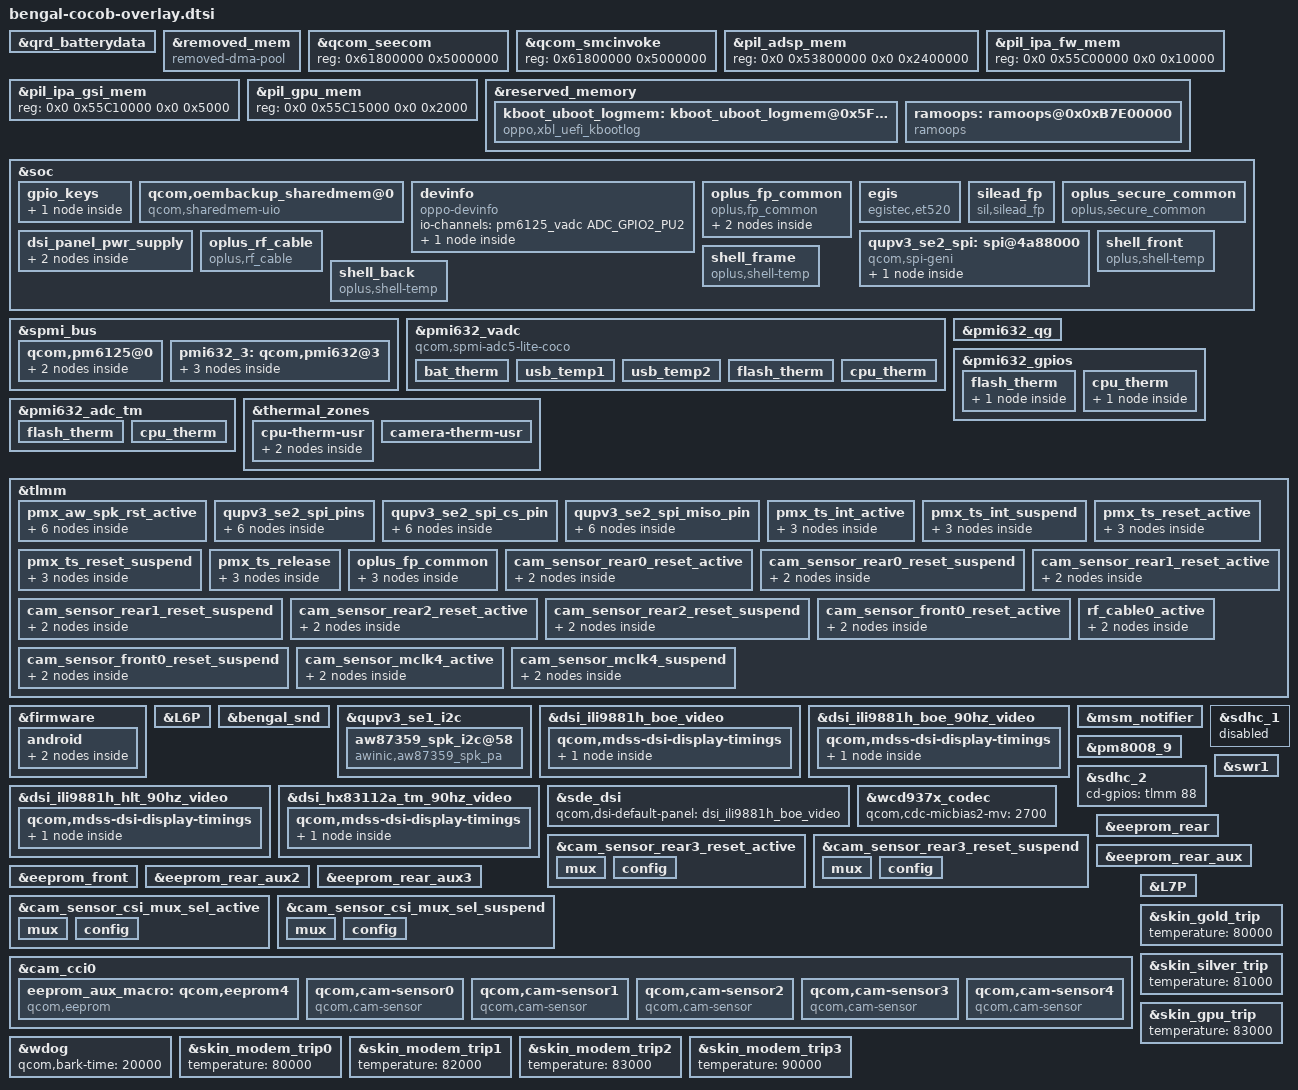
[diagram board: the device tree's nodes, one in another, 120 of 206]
/* *****************
the up part file change like:
delete note  and status = "disabled" to "ok"  add here also, other will meet can't boot issue or compile error issue
**************************/
#include "../../qcom/bengal-qrd.dtsi"
#include "dsi-panel-oplus20673-am643-samsung-fhd-video.dtsi"
#include "dsi-panel-oplus20673-s6e8fc1-samsung-fhd-video.dtsi"
//#ifdef OPLUS_BUG_STABILITY
#include "dsi-panel-ili9881h-boe-hd-vid.dtsi"
#include "dsi-panel-ili9881h-boe-hd-90hz-vid.dtsi"
#include "dsi-panel-ili9881h-hlt-hd-90hz-vid.dtsi"
#include "dsi-panel-hx83112a-tm-hd-90hz-vid.dtsi"
//#endif /* OPLUS_BUG_STABILITY */
#include "bengal-sia81xx.dtsi"

#include "nfc/coco-nfc-pn553.dtsi"

//bengal.dtsi

//#ifdef OPLUS_FEATURE_CHG_BASIC
&qrd_batterydata {
    /delete-node/ qcom,ATL466271_3300mAh;
    #include "oplus_battery_5000mah_1k_pmi632_Liwinon.dtsi"
    #include "oplus_battery_5000mah_15k_pmi632_Coslight.dtsi"
    #include "oplus_battery_5000mah_68k_pmi632_Atl.dtsi"
};
//#endif /* OPLUS_FEATURE_CHG_BASIC */
//#ifdef OPLUS_FEATURE_FINGERPRINT
&removed_mem {
	compatible = "removed-dma-pool";
	no-map;
	reg = <0x0 0x60000000 0x0 0x6800000>;
};
&qcom_seecom {
	/delete-property/ reg;
	reg = <0x61800000 0x5000000>;
};
&qcom_smcinvoke {
	/delete-property/ reg;
	reg = <0x61800000 0x5000000>;
};
//#endif /*OPLUS_FEATURE_FINGERPRINT*/

&pil_adsp_mem {
	/delete-property/ reg;
	reg = <0x0 0x53800000 0x0 0x2400000>;
};

&pil_ipa_fw_mem {
	/delete-property/ reg;
	reg = <0x0 0x55C00000 0x0 0x10000>;
};

&pil_ipa_gsi_mem {
	/delete-property/ reg;
	reg = <0x0 0x55C10000 0x0 0x5000>;
};

&pil_gpu_mem {
	/delete-property/ reg;
	reg = <0x0 0x55C15000 0x0 0x2000>;
};

// xbl_uefi_mem address get from boot_images Core.dsc.inc file: PcdEmbeddedFdBaseAddress + SERIAL_BUFFER_OFFSET,0x5FC00000+0x3F7000
// kernel boot log: 0x5FC00000~ 0x5FFF7000
&reserved_memory {

	kboot_uboot_logmem: kboot_uboot_logmem@0x5FC00000 {
		reg = <0x0 0x5FC00000 0x0 0x3FF000>;
		compatible = "oppo,xbl_uefi_kbootlog";
		xbluefi-offset = <0x3F7000>;
		no-map;
	};

	ramoops: ramoops@0x0xB7E00000 {
		compatible = "ramoops";
		reg = <0 0xB7E00000 0 0x00400000>;
		record-size =  <0x40000>; //256x1024
		console-size = <0x40000>;
		ftrace-size =  <0x40000>;
		pmsg-size=         <0x200000>;
		devinfo-size=  <0x01000>;
		ecc-size=          <0x0>;
	};
};
//bengal-qrd.dtsi
&soc {
	gpio_keys {
		vol_up {
			/delete-property/ label;
			label = "volume_down";
			/delete-property/ linux,code;
			linux,code = <KEY_VOLUMEDOWN>;
		};
	};
	//#ifdef VENDOR_EDIT
	//#ifdef FEATURE_OPPO_NV_BACKUP
	//add for creating a shared memory with uio for nv backup and restore
	qcom,oembackup_sharedmem@0 {
		compatible = "qcom,sharedmem-uio";
		reg = <0x0 0x00100000>;
		reg-names = "oembackup";
		qcom,client-id = <0x00000004>;
		qcom,guard-memory;
		qcom,vm-nav-path;
	};
	//#endif /* FEATURE_OPPO_NV_BACKUP */
	//#endif /* VENDOR_EDIT */

	devinfo {
		compatible = "oppo-devinfo";

		io-channels= <&pm6125_vadc ADC_GPIO2_PU2>;
		io-channel-names= "vph_pwr_voltage_sub";

		main-sub {
			compatible = "hw-match, main-sub";
			aboard-gpio0 = <&tlmm 68 0x1>;  //KB
			aboard-gpio1 = <&tlmm 101 0x1>; //MB
			//#ifndef VENDOR_EDIT
			//aboard-patterns = <0 0 0 0 0>;
			//#else
			aboard-patterns = <0 0 0 0 0 0>;
			//#endif

			/* main board */
			match-projects = <20671 20670 20672 20676 20679 0x2067C>;

		};
	};
	
	//#ifdef OPLUS_FEATURE_FINGERPRINT
	oplus_fp_common { //Slave driver and CS ID
        compatible = "oplus,fp_common"; //Manufacture, and Model
        oplus,fp_gpio_num = <1>;
        oplus,fp_gpio_0= <&tlmm 33 0x00>;//gpio33 ,1200 is gpio value
        pinctrl-names = "default";
        pinctrl-0 = <&gpio_id_default>;
	
        fp_egis {
		oplus,fp-id = <1>; /* fp id mapping table */
		vendor-chip = <18>; /* please refer to the struct fp_vendor_t in oppo_fp_commmon.h */
		eng-menu = "-1,-1"; /* represents SNR, inclination test item in engineer menu, and 0/1 means off/on */
		chip-name = "E_520";  /* /proc/fp_id, will be displayed in engineer menu  */
        };
		
        fp_silead {
            oplus,fp-id = <0>; /* fp id mapping table */
            vendor-chip = <21>; /* please refer to the struct fp_vendor_t in oppo_fp_commmon.h */
            eng-menu = "-1,-1"; /* represents SNR, inclination test item in engineer menu, and 0/1 means off/on */
            chip-name = "GSL_6150";  /* /proc/fp_id, will be displayed in engineer menu  */
        };
	};

	egis{
		status = "okay";
		compatible = "egistec,et520";
		interrupt-parent = <&tlmm>;
		interrupts = <34 0x00>;
		egistec,gpio_rst = <&tlmm 97 0x00>;
		egistec,gpio_irq = <&tlmm 34 0x00>;
	};
	
	silead_fp {
        compatible = "sil,silead_fp";
        qcom,qup-id = <5>;
        spi-max-frequency = <4800000>;
        reg = <0>;
        interrupt-parent = <&tlmm>;
        interrupts = <34 0x00>;
        rst-gpios = <&tlmm 97 0x00>;
        irq-gpios = <&tlmm 34 0x00>;
    };
	//#endif /*OPLUS_FEATURE_FINGERPRINT*/
    // #ifdef OPLUS_FEATURE_SECURITY_COMMON
    oplus_secure_common {
        compatible = "oplus,secure_common";
    };
    //#endif /* OPLUS_FEATURE_SECURITY_COMMON */

	//#ifdef OPLUS_BUG_STABILITY
	dsi_panel_pwr_supply {
		qcom,panel-supply-entry@1 {
			qcom,supply-min-voltage = <4600000>;
		};
		qcom,panel-supply-entry@2 {
			qcom,supply-min-voltage = <4600000>;
			qcom,supply-post-on-sleep = <2>;
		};
	};
	//#endif /* OPLUS_BUG_STABILITY */
        qupv3_se2_spi: spi@4a88000 {
                compatible = "qcom,spi-geni";
                #address-cells = <1>;
                #size-cells = <0>;
                reg = <0x4a88000 0x4000>;
                reg-names = "se_phys";
                clock-names = "se-clk", "m-ahb", "s-ahb";
                clocks = <&gcc GCC_QUPV3_WRAP0_S2_CLK>,
                        <&gcc GCC_QUPV3_WRAP_0_M_AHB_CLK>,
                        <&gcc GCC_QUPV3_WRAP_0_S_AHB_CLK>;
                pinctrl-names = "default", "sleep";
                pinctrl-0 = <&qupv3_se2_spi_active &qupv3_se2_spi_miso_active &qupv3_se2_spi_cs_active>;
                pinctrl-1 = <&qupv3_se2_spi_sleep &qupv3_se2_spi_miso_sleep &qupv3_se2_spi_cs_sleep>;

                interrupts = <GIC_SPI 329 IRQ_TYPE_LEVEL_HIGH>;
                spi-max-frequency = <50000000>;
                qcom,wrapper-core = <&qupv3_0>;
                dmas = <&gpi_dma0 0 2 1 64 0>,
                        <&gpi_dma0 1 2 1 64 0>;
                dma-names = "tx", "rx";
                status = "disabled";
        };
	//#ifdef VENDOR_EDIT
	oplus_rf_cable {
		compatible = "oplus,rf_cable";
		interrupt-parent = <&tlmm>;
		rf_cable_support_num = <1>;
		rf,cable0-gpio = <&tlmm 39 0>;
		rf,cable-support-timer = <0>;
		pinctrl-names = "rf_cable_active";
		pinctrl-0 = <&rf_cable0_active>;
	};
	//#endif /* VENDOR_EDIT */
	//#ifdef OPLUS_FEATURE_THERMAL_HORAE
	shell_front {
		compatible = "oplus,shell-temp";
	};

	shell_frame {
		compatible = "oplus,shell-temp";
	};

	shell_back {
		compatible = "oplus,shell-temp";
	};
	//#endif /* OPLUS_FEATURE_THERMAL_HORAE */
};
&spmi_bus {
	qcom,pm6125@0 {
		qcom,power-on@800 {
			qcom,pon_2 {
				qcom,pon-type = <1>;
				qcom,pull-up = <1>;
				linux,code = <KEY_VOLUMEUP>;
			};
		};
    };
        //#ifdef OPLUS_BUG_STABILITY
	pmi632_3: qcom,pmi632@3 {
		pmi632_lcdb: qpnp-lcdb@ec00 {
			qcom,pwrdn-delay-ms = <8>; //Possible values are 0, 1, 4, 8.
			lcdb_ldo_vreg: ldo {
				qcom,ldo-voltage-mv = <6000>;
			};
			lcdb_ncp_vreg: ncp {
				qcom,ldo-voltage-mv = <6000>;
			};
		};
	};
	//#endif /* OPLUS_BUG_STABILITY */
	//#ifdef OPLUS_FEATURE_CHG_BASIC

	//#endif /* OPLUS_FEATURE_CHG_BASIC */
};
//#ifdef OPLUS_FEATURE_CHG_BASIC
&pmi632_vadc{
			compatible = "qcom,spmi-adc5-lite-coco";
			bat_therm {
			    /delete-property/ reg;
			    reg = <ADC_BAT_THERM_PU1>;
		            qcom,lut-index = <2>;
			};
			usb_temp1 {
				reg = <ADC_GPIO1_PU2>;
				label = "usb_temp1";
				qcom,pre-scaling = <1 1>;
			};
			usb_temp2 {
				reg = <ADC_GPIO3_PU2>;
				label = "usb_temp2";
				qcom,pre-scaling = <1 1>;
			};
		};
&pmi632_qg{
		    /delete-property/ io-channels;
		    io-channels = <&pmi632_vadc ADC_BAT_THERM_PU1>,
		    		  <&pmi632_vadc ADC_PARALLEL_ISENSE>,
		                  <&pmi632_vadc ADC_BAT_ID_PU2>;
		    /delete-property/ io-channel-names;
	            io-channel-names = "batt-therm",
		                       "parallel_isense",
		                       "batt-id";
		    qcom,s3-entry-ibat-ua = <25000>;
		    qcom,s3-exit-ibat-ua = <38000>;
		    qcom,vbatt-cutoff-mv = <3390>;
		    qcom,fvss-enable;
                    qcom,project-index = <2>;// soda = 0; rum = 1; coco = 2
		    qcom,enable-qpnp-qg;	
		};
&pmi632_vadc {
    /delete-property/ pinctrl-0;
    pinctrl-0 = <&conn_therm_default &skin_therm_default &flash_therm_default &cpu_therm_default>;

	flash_therm {
		reg = <ADC_AMUX_THM1_PU2>;
		label = "flash_therm";
		qcom,ratiometric;
		qcom,hw-settle-time = <200>;
		qcom,pre-scaling = <1 1>;
	};

	cpu_therm {
		reg = <ADC_GPIO4_PU2>;
		label = "cpu_therm";
		qcom,ratiometric;
		qcom,hw-settle-time = <200>;
		qcom,pre-scaling = <1 1>;
	};	
};

&pmi632_gpios {
	flash_therm {
		flash_therm_default: flash_therm_default {
			pins = "gpio5";
			bias-high-impedance;
		};
	};

	cpu_therm {
		cpu_therm_default: cpu_therm_default {
			pins = "gpio6";
			bias-high-impedance;
		};
	};
};

&pmi632_adc_tm {
    /delete-property/ io-channels;
    io-channels = <&pmi632_vadc ADC_GPIO2_PU2>,
                  <&pmi632_vadc ADC_AMUX_THM1_PU2>,
		  <&pmi632_vadc ADC_GPIO4_PU2>;
		  
	flash_therm {
		reg = <ADC_AMUX_THM1_PU2>;
		qcom,ratiometric;
		qcom,hw-settle-time = <200>;
	};

	cpu_therm {
		reg = <ADC_GPIO4_PU2>;
		qcom,ratiometric;
		qcom,hw-settle-time = <200>;
	};
};

&thermal_zones {
    cpu-therm-usr {
	polling-delay-passive = <0>;
	polling-delay = <0>;
	thermal-governor = "user_space";
	thermal-sensors = <&pmi632_adc_tm ADC_GPIO4_PU2>;
	wake-capable-sensor;
	trips {
		active-config0 {
			temperature = <125000>;
			hysteresis = <1000>;
			type = "passive";
		};
	};
    };
    camera-therm-usr {
    /delete-property/ thermal-sensors;
    thermal-sensors = <&pmi632_adc_tm ADC_AMUX_THM1_PU2>;
    };
};
//#endif /* OPLUS_FEATURE_CHG_BASIC */
&tlmm {
	pmx_aw_spk_rst_active {
		aw_spk_reset_on: aw_spk_reset_on {
			mux {
				pins = "gpio111";
				function = "gpio";
			};

			config {
				pins = "gpio111";
				drive-strength = <8>;
				bias-pull-up;
			};
		};

		aw_spk_reset_off: aw_spk_reset_off {
			mux {
				pins = "gpio111";
				function = "gpio";
			};

			config {
				pins = "gpio111";
				drive-strength = <2>;
				bias-pull-down;
			};
		};
	};
	
	qupv3_se2_spi_pins: qupv3_se2_spi_pins {
		qupv3_se2_spi_active: qupv3_se2_spi_active {
			mux {
				pins = "gpio7", "gpio71";
				function = "qup2";
			};

			config {
				pins = "gpio7", "gpio71";
				drive-strength = <8>;
				output-low;
				bias-disable;
			};
		};

		qupv3_se2_spi_sleep: qupv3_se2_spi_sleep {
			mux {
				pins = "gpio7", "gpio71";
				function = "qup2";
			};

			configs {
				pins = "gpio7", "gpio71";
				drive-strength = <8>;
				output-low;
				bias-disable;
			};
		};
	};

	qupv3_se2_spi_cs_pin: qupv3_se2_spi_cs_pin {
		qupv3_se2_spi_cs_active: qupv3_se2_spi_cs_active {
			mux {
				pins = "gpio80";
				function = "qup2";
			};

			config {
				pins = "gpio80";
				drive-strength = <8>;
				output-high;
				bias-disable;
			};
		};

		qupv3_se2_spi_cs_sleep: qupv3_se2_spi_cs_sleep {
			mux {
				pins = "gpio80";
				function = "qup2";
			};

			configs {
				pins = "gpio80";
				drive-strength = <8>;
				output-high;
				bias-disable;
			};
		};
	};

	qupv3_se2_spi_miso_pin: qupv3_se2_spi_miso_pin {
		qupv3_se2_spi_miso_active: qupv3_se2_spi_miso_active {
			mux {
				pins = "gpio6";
				function = "qup2";
			};

			config {
				pins = "gpio6";
				drive-strength = <8>;
				bias-disable;
			};
		};

		qupv3_se2_spi_miso_sleep: qupv3_se2_spi_miso_sleep {
			mux {
				pins = "gpio6";
				function = "qup2";
			};

			configs {
				pins = "gpio6";
				drive-strength = <8>;
				bias-disable;
			};
		};
	};

	pmx_ts_int_active {
		ts_int_active: ts_int_active {
			mux {
				pins = "gpio104";
				function = "gpio";
			};

			config {
				pins = "gpio104";
				drive-strength = <8>;
				bias-pull-up;
			};
		};
	};

	pmx_ts_int_suspend {
		ts_int_suspend: ts_int_suspend {
			mux {
				pins = "gpio104";
				function = "gpio";
			};

			config {
				pins = "gpio104";
				drive-strength = <2>;
				bias-pull-up;
			};
		};
	};

	pmx_ts_reset_active {
		ts_reset_active: ts_reset_active {
			mux {
				pins = "gpio103";
				function = "gpio";
			};

			config {
				pins = "gpio103";
				drive-strength = <8>;
				bias-pull-up;
			};
		};
	};

	pmx_ts_reset_suspend {
		ts_reset_suspend: ts_reset_suspend {
			mux {
				pins = "gpio103";
				function = "gpio";
			};

			config {
				pins = "gpio103";
				drive-strength = <2>;
				bias-pull-down;
			};
		};
	};

	pmx_ts_release {
		ts_release: ts_release {
			mux {
				pins = "gpio103", "gpio104";
				function = "gpio";
			};

			config {
				pins = "gpio103", "gpio104";
				drive-strength = <2>;
				bias-pull-down;
			};
		};
	};
	
    //#ifdef OPLUS_FEATURE_FINGERPRINT
    oplus_fp_common{
		gpio_id_default: gpio_id_default {
			mux {
				pins = "gpio33";
				function = "gpio";
			};
			config {
				pins = "gpio33";
				drive-strength = <2>;
				bias-pull-up;
				input-enable;
			};
		};
	};
    //#endif
    
};

&firmware {
	android {
		fstab {
			vendor {
				/delete-property/ fsmgr_flags;
				fsmgr_flags = "wait,avb";
			};
		};
	};
};

&L6P {
	/delete-property/ regulator-min-microvolt;
	/delete-property/ regulator-max-microvolt;
	regulator-min-microvolt = <2800000>;
	regulator-max-microvolt = <3400000>;
};

&bengal_snd {
	/delete-property/ qcom,wsa-max-devs;
	/delete-property/ qcom,wsa-devs;
	qcom,wsa-max-devs = <0>;
	qcom,wsa-devs = <0>;
};

&qupv3_se1_i2c {
	/delete-node/ nq;

	aw87359_spk_i2c@58{
		compatible = "awinic,aw87359_spk_pa";
		reg = <0x58>;
		reset-gpio = <&tlmm 111 0x00>;
		pinctrl-names = "spk_reset_on", "spk_reset_off";
		pinctrl-0 = <&aw_spk_reset_on>;
		pinctrl-1 = <&aw_spk_reset_off>;
	};
};
&qupv3_se2_spi {
        /* Himax device tree node */
        status = "ok";
        ilitek_spi@0 {
                compatible = "tchip,ilitek";
                reg = <0>;
                chip-name = "NF_ILI9881H";
                status = "ok";

                spi-max-frequency = <12000000>;    //4800000,9600000,15000000,19200000
                reset-gpio = <&tlmm 103 0x00>;
                interrupt-parent = <&tlmm>;
                interrupts = <104 0x0>;
                irq-gpio = <&tlmm 104 0x2002>;

                touchpanel,max-num-support = <10>;
                touchpanel,tx-rx-num = <18 32>;
                touchpanel,panel-coords = <720 1600>;
                touchpanel,display-coords = <720 1600>;
                touchpanel,touchmajor-limit = <0 54>;

                platform_support_project = <20670 20671 20672 20676 20679 0x2067C>;
                platform_support_project_dir = <20671 20671 20671 20671 20671 20671>;
                platform_support_project_commandline = "ili9881h", "ili9881h", "ili9881h", "ili9881h", "ili9881h", "ili9881h";
                pinctrl-names = "default", "suspend";
                pinctrl-0 = <&ts_int_active &ts_reset_active>;
                pinctrl-1 = <&ts_int_suspend &ts_reset_suspend>;

                incell_screen;
                irq_need_dev_resume_ok;
                fw_edge_limit_support;
                black_gesture_support;
                charger_pump_support;
                headset_pump_support;
                esd_handle_support;
                //spurious_fingerprint_support;
                //lcd_trigger_fp_check;
                black_gesture_test_support;
                noflash_support;
                smart_gesture_support;
                pressure_report_support;
                fw_update_app_support;
                game_switch_support;
                drlimit_remove_support;
                lcd_trigger_load_tp_fw_support;
                suspend_gesture_cfg;
                fw_update_in_probe_with_headfile;

                touchpanel,button-type = <4>;
        };
};

//#ifdef OPLUS_BUG_STABILITY
&dsi_ili9881h_boe_video {
	qcom,panel-supply-entries = <&dsi_panel_pwr_supply>;
	qcom,mdss-dsi-bl-pmic-control-type = "bl_ctrl_dcs";
	pwms = <&pm6125_pwm 0 0>;
	qcom,bl-pmic-pwm-period-usecs = <100>;
	qcom,mdss-dsi-bl-min-level = <1>;
	qcom,mdss-dsi-bl-max-level = <4095>;
	qcom,mdss-brightness-max-level = <4095>;
	qcom,mdss-dsi-bl-normal-max-level = <2047>;
	qcom,mdss-brightness-normal-max-level = <2047>;
	qcom,mdss-brightness-default-level = <1024>;
	qcom,platform-reset-gpio = <&tlmm 85 0>;
	oplus,backlight-enable;
	//qcom,platform-bklight-en-gpio = <&pmi632_gpios 6 0>;
};
&dsi_ili9881h_boe_90hz_video {
	qcom,panel-supply-entries = <&dsi_panel_pwr_supply>;
	qcom,mdss-dsi-bl-pmic-control-type = "bl_ctrl_dcs";
	pwms = <&pm6125_pwm 0 0>;
	qcom,bl-pmic-pwm-period-usecs = <100>;
	qcom,mdss-dsi-bl-min-level = <1>;
	qcom,mdss-dsi-bl-max-level = <4095>;
	qcom,mdss-brightness-max-level = <4095>;
	qcom,mdss-dsi-bl-normal-max-level = <2047>;
	qcom,mdss-brightness-normal-max-level = <2047>;
	qcom,mdss-brightness-default-level = <1024>;
	qcom,platform-te-gpio = <&tlmm 81 0>;
	qcom,platform-reset-gpio = <&tlmm 85 0>;
	oplus,backlight-enable;
	//qcom,platform-bklight-en-gpio = <&pmi632_gpios 6 0>;
};

&dsi_ili9881h_hlt_90hz_video {
	qcom,panel-supply-entries = <&dsi_panel_pwr_supply>;
	qcom,mdss-dsi-bl-pmic-control-type = "bl_ctrl_dcs";
	pwms = <&pm6125_pwm 0 0>;
	qcom,bl-pmic-pwm-period-usecs = <100>;
	qcom,mdss-dsi-bl-min-level = <1>;
	qcom,mdss-dsi-bl-max-level = <4095>;
	qcom,mdss-brightness-max-level = <4095>;
	qcom,mdss-dsi-bl-normal-max-level = <2047>;
	qcom,mdss-brightness-normal-max-level = <2047>;
	qcom,mdss-brightness-default-level = <1024>;
	qcom,platform-reset-gpio = <&tlmm 85 0>;
	oplus,backlight-enable;
	//qcom,platform-bklight-en-gpio = <&pmi632_gpios 6 0>;
};

&dsi_hx83112a_tm_90hz_video {
	qcom,panel-supply-entries = <&dsi_panel_pwr_supply>;
	qcom,mdss-dsi-bl-pmic-control-type = "bl_ctrl_dcs";
	pwms = <&pm6125_pwm 0 0>;
	qcom,bl-pmic-pwm-period-usecs = <100>;
	qcom,mdss-dsi-bl-min-level = <1>;
	qcom,mdss-dsi-bl-max-level = <4095>;
	qcom,mdss-brightness-max-level = <4095>;
	qcom,mdss-dsi-bl-normal-max-level = <2047>;
	qcom,mdss-brightness-normal-max-level = <2047>;
	qcom,mdss-brightness-default-level = <1024>;
	qcom,platform-reset-gpio = <&tlmm 85 0>;
	oplus,backlight-enable;
	//qcom,platform-bklight-en-gpio = <&pmi632_gpios 6 0>;
};
//#endif /* OPLUS_BUG_STABILITY */

&sde_dsi {
	/delete-property/ qcom,dsi-default-panel;
	qcom,dsi-default-panel = <&dsi_ili9881h_boe_video>;
};
&msm_notifier {
	/delete-property/ panel;
	panel = <&dsi_s6e8fc1_samsung_video
		&dsi_s6e8fc1_samsung_video>;
};

&pm8008_9{
	status = "okay";
};

/* #ifdef OPLUS_FEATURE_EMMC_DRIVER */
&sdhc_1 {
       status = "disabled";
};

&sdhc_2 {
       cd-gpios = <&tlmm 88 GPIO_ACTIVE_HIGH>;
       status = "ok";
};
/* #endif */

//bengal-audio-overlay.dtsi
&swr1 {
	/delete-property/ qcom,disable-div2-clk-switch;
};
&wcd937x_codec {
	/delete-property/ qcom,cdc-micbias2-mv;
	qcom,cdc-micbias2-mv = <2700>;
};

&bengal_snd {
	/delete-property/ qcom,wsa-max-devs;
	/delete-property/ qcom,wsa-devs;
	qcom,wsa-max-devs = <0>;
	qcom,wsa-devs = <0>;
};

//bengal-camera-sensor-qrd.dtsi
&tlmm {
	cam_sensor_rear0_reset_active: cam_sensor_rear0_reset_active {
		mux {
			pins = "gpio18";
			function = "gpio";
		};
		config {
			pins = "gpio18";
			bias-disable; /* No PULL */
			drive-strength = <2>; /* 2 MA */
		};
	};
	cam_sensor_rear0_reset_suspend: cam_sensor_rear0_reset_suspend {
		mux {
			pins = "gpio18";
			function = "gpio";
		};
		config {
			pins = "gpio18";
			bias-pull-down; /* PULL DOWN */
			drive-strength = <2>; /* 2 MA */
			output-low;
		};
	};
	cam_sensor_rear1_reset_active: cam_sensor_rear1_reset_active {
		mux {
			pins = "gpio19";
			function = "gpio";
		};
		config {
			pins = "gpio19";
			bias-disable; /* No PULL */
			drive-strength = <2>; /* 2 MA */
		};
	};
	cam_sensor_rear1_reset_suspend: cam_sensor_rear1_reset_suspend {
		mux {
			pins = "gpio19";
			function = "gpio";
		};
		config {
			pins = "gpio19";
			bias-pull-down; /* PULL DOWN */
			drive-strength = <2>; /* 2 MA */
			output-low;
		};
	};
	cam_sensor_rear2_reset_active: cam_sensor_rear2_reset_active {
		mux {
			pins = "gpio65";
			function = "gpio";
		};
		config {
			pins = "gpio65";
			bias-disable; /* No PULL */
			drive-strength = <2>; /* 2 MA */
		};
	};
	cam_sensor_rear2_reset_suspend: cam_sensor_rear2_reset_suspend {
		mux {
			pins = "gpio65";
			function = "gpio";
		};
		config {
			pins = "gpio65";
			bias-pull-down; /* PULL DOWN */
			drive-strength = <2>; /* 2 MA */
			output-low;
		};
	};
	cam_sensor_front0_reset_active: cam_sensor_front0_reset_active {
		mux {
			pins = "gpio24";
			function = "gpio";
		};
		config {
			pins = "gpio24";
			bias-disable; /* No PULL */
			drive-strength = <2>; /* 2 MA */
		};
	};
	cam_sensor_front0_reset_suspend: cam_sensor_front0_reset_suspend {
		mux {
			pins = "gpio24";
			function = "gpio";
		};
		config {
			pins = "gpio24";
			bias-pull-down; /* PULL DOWN */
			drive-strength = <2>; /* 2 MA */
			output-low;
		};
	};

	cam_sensor_mclk4_active: cam_sensor_mclk4_active {
		/* MCLK 4*/
		mux {
			pins = "gpio28";
			function = "cam_mclk";
		};

		config {
			pins = "gpio28";
			bias-disable; /* No PULL */
			drive-strength = <2>; /* 2 MA */
		};
	};

	cam_sensor_mclk4_suspend: cam_sensor_mclk4_suspend {
		/* MCLK 4*/
		mux {
			pins = "gpio28";
			function = "cam_mclk";
		};

		config {
			pins = "gpio28";
			bias-pull-down; /* PULL DOWN */
			drive-strength = <2>; /* 2 MA */
		};
	};
	//#ifdef VENDOR_EDIT
	rf_cable0_active: rf_cable0_active {
		mux {
			pins = "gpio39";
			function = "gpio";
		};
		config {
			pins = "gpio39";
			drive-strength = <2>;
			input-enable;
			bias-pull-up;
		};
	};
	//#endif /* VENDOR_EDIT */	
	

};

&cam_sensor_rear3_reset_active {
	mux {
		pins = "gpio32";
		function = "gpio";
	};
	config {
		pins = "gpio32";
		bias-disable; /* No PULL */
		drive-strength = <2>; /* 2 MA */
	};
};
&cam_sensor_rear3_reset_suspend {
	mux {
		pins = "gpio32";
		function = "gpio";
	};
	config {
		pins = "gpio32";
		bias-disable; /* No PULL */
		drive-strength = <2>; /* 2 MA */
	};
};
&L6P {
	regulator-min-microvolt = <1800000>;
	regulator-max-microvolt = <1800000>;
};
&eeprom_rear {
	/delete-property/ cam_vio-supply;
	/delete-property/ gpios;
	cam_vio-supply = <&L6P>;
	pinctrl-0 = <&cam_sensor_mclk0_active
				&cam_sensor_rear0_reset_active>;
	pinctrl-1 = <&cam_sensor_mclk0_suspend
				&cam_sensor_rear0_reset_suspend>;
	gpios = <&tlmm 20 0>,
			<&tlmm 18 0>;
	gpio-reset = <1>;
	gpio-req-tbl-num = <0 1>;
	gpio-req-tbl-flags = <1 0>;
	gpio-req-tbl-label = "CAMIF_MCLK0",
						"CAM_RESET0";
	sensor-mode = <0>;
	cci-master = <0>;
	status = "ok";
	clocks = <&gcc GCC_CAMSS_MCLK0_CLK>;
	clock-names = "cam_clk";
	clock-cntl-level = "turbo";
	clock-rates = <24000000>;
};

&eeprom_rear_aux {
	/delete-property/ cam_vio-supply;
	/delete-property/ pinctrl-0;
	/delete-property/ pinctrl-1;
	/delete-property/ gpios;
	/delete-property/ gpio-req-tbl-label;
	/delete-property/ clocks;
	cam_vio-supply = <&L6P>;
	pinctrl-0 = <&cam_sensor_mclk1_active
				&cam_sensor_rear1_reset_active>;
	pinctrl-1 = <&cam_sensor_mclk1_suspend
				&cam_sensor_rear1_reset_suspend>;
	gpios = <&tlmm 21 0>,
			<&tlmm 19 0>;
	gpio-reset = <1>;
	gpio-req-tbl-num = <0 1>;
	gpio-req-tbl-flags = <1 0>;
	gpio-req-tbl-label = "CAMIF_MCLK1",
						"CAM_RESET1";
	sensor-mode = <0>;
	cci-master = <1>;
	status = "ok";
	clocks = <&gcc GCC_CAMSS_MCLK1_CLK>;
	clock-names = "cam_clk";
	clock-cntl-level = "turbo";
	clock-rates = <19200000>;
};

&eeprom_front {
	/delete-property/ cam_vio-supply;
	/delete-property/ pinctrl-0;
	/delete-property/ pinctrl-1;
	/delete-property/ gpios;
	/delete-property/ gpio-req-tbl-label;
	/delete-property/ clocks;
	cam_vio-supply = <&L6P>;
	pinctrl-0 = <&cam_sensor_mclk2_active
				&cam_sensor_front0_reset_active>;
	pinctrl-1 = <&cam_sensor_mclk2_suspend
				&cam_sensor_front0_reset_suspend>;
	gpios = <&tlmm 27 0>,
			<&tlmm 24 0>;
	gpio-reset = <1>;
	gpio-req-tbl-num = <0 1>;
	gpio-req-tbl-flags = <1 0>;
	gpio-req-tbl-label = "CAMIF_MCLK2",
						"CAM_RESET2";
	sensor-mode = <0>;
	cci-master = <1>;
	status = "ok";
	clocks = <&gcc GCC_CAMSS_MCLK2_CLK>;
	clock-names = "cam_clk";
	clock-cntl-level = "turbo";
	clock-rates = <24000000>;
};

&eeprom_rear_aux2 {
	/delete-property/ cam_vio-supply;
	/delete-property/ pinctrl-0;
	/delete-property/ pinctrl-1;
	/delete-property/ gpios;
	/delete-property/ gpio-req-tbl-label;
	/delete-property/ clocks;
	/delete-property/ cci-master;
	cam_vio-supply = <&L6P>;
	pinctrl-0 = <&cam_sensor_mclk4_active
				&cam_sensor_rear3_reset_active
				&cam_sensor_csi_mux_sel_active>;
	pinctrl-1 = <&cam_sensor_mclk4_suspend
				&cam_sensor_rear3_reset_suspend
				&cam_sensor_csi_mux_sel_suspend>;
	gpios = <&tlmm 28 0>,
			<&tlmm 32 0>,
			<&tlmm 59 0>;
	gpio-reset = <1>;
	gpio-custom1 = <2>;
	gpio-req-tbl-num = <0 1 2>;
	gpio-req-tbl-flags = <1 0 0>;
	gpio-req-tbl-label = "CAMIF_MCLK4",
						"CAM_RESET4",
						"CAM_CSIMUX_SEL1";
	sensor-mode = <0>;
	cci-master = <0>;
	status = "ok";
	clocks = <&gcc GCC_CAMSS_MCLK3_CLK>;
	clock-names = "cam_clk";
	clock-cntl-level = "turbo";
	clock-rates = <24000000>;
};

&eeprom_rear_aux3 {
	/delete-property/ cam_vio-supply;
	/delete-property/ pinctrl-0;
	/delete-property/ pinctrl-1;
	/delete-property/ gpios;
	/delete-property/ gpio-req-tbl-label;
	/delete-property/ clocks;
	/delete-property/ cci-master;
	cam_vio-supply = <&L6P>;
	pinctrl-0 = <&cam_sensor_mclk2_active
				&cam_sensor_rear3_reset_active>;
	pinctrl-1 = <&cam_sensor_mclk2_suspend
				&cam_sensor_rear3_reset_suspend>;
	gpios = <&tlmm 27 0>,
			<&tlmm 18 0>;
	gpio-req-tbl-label = "CAMIF_MCLK2",
						"CAM_RESET4";
	cci-master = <1>;
	clocks = <&gcc GCC_CAMSS_MCLK2_CLK>;
};

&cam_sensor_csi_mux_sel_active {
	/*CSIMUX_SEL*/
	mux {
		pins = "gpio59";
		function = "gpio";
	};

	config {
		pins = "gpio59";
		bias-disable; /* No PULL */
		drive-strength = <2>; /* 2 MA */
	};
};
&cam_sensor_csi_mux_sel_suspend {
	/* CSIMUX_SEL */
	mux {
		pins = "gpio59";
		function = "gpio";
	};

	config {
		pins = "gpio59";
		bias-pull-down; /* PULL DOWN */
		drive-strength = <2>; /* 2 MA */
		output-low;
	};
};

&cam_cci0 {
	eeprom_aux_macro: qcom,eeprom4 {
		cell-index = <4>;
		compatible = "qcom,eeprom";
		cam_vio-supply = <&L6P>;
		cam_vana-supply = <&L4P>;
		cam_clk-supply = <&gcc_camss_top_gdsc>;
		regulator-names = "cam_vio", "cam_vana","cam_clk";
		rgltr-cntrl-support;
		pwm-switch;
		rgltr-min-voltage = <1800000 2800000 0>;
		rgltr-max-voltage = <1800000 2800000 0>;
		rgltr-load-current = <120000 80000 0>;
		gpio-no-mux = <0>;
		pinctrl-names = "cam_default", "cam_suspend";
		pinctrl-0 = <&cam_sensor_mclk4_active
				&cam_sensor_rear3_reset_active>;
		pinctrl-1 = <&cam_sensor_mclk4_suspend
				&cam_sensor_rear3_reset_suspend>;
		gpios = <&tlmm 28 0>,
			<&tlmm 32 0>;
		gpio-reset = <1>;
		gpio-req-tbl-num = <0 1>;
		gpio-req-tbl-flags = <1 0>;
		gpio-req-tbl-label = "CAMIF_MCLK4",
					"CAM_RESET4";
		sensor-mode = <0>;
		cci-master = <0>;
		status = "ok";
		clocks = <&gcc GCC_CAMSS_MCLK3_CLK>;
		clock-names = "cam_clk";
		clock-cntl-level = "turbo";
		clock-rates = <24000000>;
	};

	/* Rear*/
	qcom,cam-sensor0 {
		cell-index = <0>;
		compatible = "qcom,cam-sensor";
		csiphy-sd-index = <0>;
		sensor-position-roll = <90>;
		sensor-position-pitch = <0>;
		sensor-position-yaw = <180>;
		actuator-src = <&actuator_rear>;
		led-flash-src = <&led_flash_rear>;
		eeprom-src = <&eeprom_rear>;
		cam_vio-supply = <&L6P>;
		cam_vana-supply = <&L3P>;
		cam_vdig-supply = <&L1P>;
		cam_clk-supply = <&gcc_camss_top_gdsc>;
		cam_vaf-supply = <&L5P>;
		regulator-names = "cam_vio", "cam_vana", "cam_vdig",
			"cam_clk", "cam_vaf";
		rgltr-cntrl-support;
		pwm-switch;
		rgltr-min-voltage = <1800000 2800000 1200000 0 2800000>;
		rgltr-max-voltage = <1800000 2800000 1200000 0 2800000>;
		rgltr-load-current = <120000 80000 1200000 0 100000>;
		gpio-no-mux = <0>;
		pinctrl-names = "cam_default", "cam_suspend";
		pinctrl-0 = <&cam_sensor_mclk0_active
				&cam_sensor_rear0_reset_active>;
		pinctrl-1 = <&cam_sensor_mclk0_suspend
				&cam_sensor_rear0_reset_suspend>;
		gpios = <&tlmm 20 0>,
			<&tlmm 18 0>;
		gpio-reset = <1>;
		gpio-req-tbl-num = <0 1>;
		gpio-req-tbl-flags = <1 0>;
		gpio-req-tbl-label = "CAMIF_MCLK0",
					"CAM_RESET0";
		sensor-mode = <0>;
		cci-master = <0>;
		status = "ok";
		clocks = <&gcc GCC_CAMSS_MCLK0_CLK>;
		clock-names = "cam_clk";
		clock-cntl-level = "turbo";
		clock-rates = <24000000>;
	};

	/* Rear wide*/
	qcom,cam-sensor1 {
		cell-index = <1>;
		compatible = "qcom,cam-sensor";
		csiphy-sd-index = <1>;
		sensor-position-roll = <90>;
		sensor-position-pitch = <0>;
		sensor-position-yaw = <180>;
		//actuator-src = <&actuator_rear>;
		led-flash-src = <&led_flash_rear_aux>;
		eeprom-src = <&eeprom_rear_aux>;
		cam_vio-supply = <&L6P>;
		cam_vana-supply = <&L4P>;
		cam_vdig-supply = <&L2P>;
		cam_clk-supply = <&gcc_camss_top_gdsc>;
		regulator-names = "cam_vio", "cam_vana", "cam_vdig",
			"cam_clk";
		rgltr-cntrl-support;
		pwm-switch;
		rgltr-min-voltage = <1800000 2800000 1200000 0>;
		rgltr-max-voltage = <1800000 2800000 1200000 0>;
		rgltr-load-current = <120000 80000 1200000 0>;
		gpio-no-mux = <0>;
		pinctrl-names = "cam_default", "cam_suspend";
		pinctrl-0 = <&cam_sensor_mclk1_active
				&cam_sensor_rear1_reset_active>;
		pinctrl-1 = <&cam_sensor_mclk1_suspend
				&cam_sensor_rear1_reset_suspend>;
		gpios = <&tlmm 21 0>,
			<&tlmm 19 0>;
		gpio-reset = <1>;
		gpio-req-tbl-num = <0 1>;
		gpio-req-tbl-flags = <1 0>;
		gpio-req-tbl-label = "CAMIF_MCLK1",
					"CAM_RESET1";
		sensor-mode = <0>;
		cci-master = <1>;
		status = "ok";
		clocks = <&gcc GCC_CAMSS_MCLK1_CLK>;
		clock-names = "cam_clk";
		clock-cntl-level = "turbo";
		clock-rates = <19200000>;
	};

    /* Front*/
	qcom,cam-sensor2 {
		cell-index = <2>;
		compatible = "qcom,cam-sensor";
		csiphy-sd-index = <2>;
		sensor-position-roll = <270>;
		sensor-position-pitch = <0>;
		sensor-position-yaw = <0>;
		//actuator-src = <&actuator_rear>;
		//led-flash-src = <&led_flash_rear>;
		eeprom-src = <&eeprom_front>;
		cam_vio-supply = <&L6P>;
		cam_vana-supply = <&L4P>;
		cam_vdig-supply = <&L2P>;
		cam_clk-supply = <&gcc_camss_top_gdsc>;
		regulator-names = "cam_vio", "cam_vana", "cam_vdig",
			"cam_clk";
		rgltr-cntrl-support;
		pwm-switch;
		rgltr-min-voltage = <1800000 2800000 1200000 0>;
		rgltr-max-voltage = <1800000 2800000 1200000 0>;
		rgltr-load-current = <120000 80000 1200000 0>;
		gpio-no-mux = <0>;
		pinctrl-names = "cam_default", "cam_suspend";
		pinctrl-0 = <&cam_sensor_mclk2_active
				&cam_sensor_front0_reset_active>;
		pinctrl-1 = <&cam_sensor_mclk2_suspend
				&cam_sensor_front0_reset_suspend>;
		gpios = <&tlmm 27 0>,
			<&tlmm 24 0>;
		gpio-reset = <1>;
		gpio-req-tbl-num = <0 1>;
		gpio-req-tbl-flags = <1 0>;
		gpio-req-tbl-label = "CAMIF_MCLK2",
					"CAM_RESET2";
		sensor-mode = <0>;
		cci-master = <1>;
		status = "ok";
		clocks = <&gcc GCC_CAMSS_MCLK2_CLK>;
		clock-names = "cam_clk";
		clock-cntl-level = "turbo";
		clock-rates = <24000000>;
	};

	/*Aux Mono*/
	qcom,cam-sensor3 {
		cell-index = <3>;
		compatible = "qcom,cam-sensor";
		csiphy-sd-index = <1>;
		sensor-position-roll = <90>;
		sensor-position-pitch = <0>;
		sensor-position-yaw = <180>;
		//actuator-src = <&actuator_rear>;
		//led-flash-src = <&led_flash_rear>;
		//eeprom-src = <&eeprom_rear>;
		cam_vio-supply = <&L6P>;
		cam_vana-supply = <&L4P>;
		//cam_vdig-supply = <&L2P>;
		cam_clk-supply = <&gcc_camss_top_gdsc>;
		regulator-names = "cam_vio", "cam_vana", "cam_clk";
		rgltr-cntrl-support;
		pwm-switch;
		rgltr-min-voltage = <1800000 2800000 0>;
		rgltr-max-voltage = <1800000 2800000 0>;
		rgltr-load-current = <120000 80000 0>;
		gpio-no-mux = <0>;
		pinctrl-names = "cam_default", "cam_suspend";
		pinctrl-0 = <&cam_sensor_mclk3_active
				&cam_sensor_rear2_reset_active
				&cam_sensor_csi_mux_sel_active>;
		pinctrl-1 = <&cam_sensor_mclk3_suspend
				&cam_sensor_rear2_reset_suspend
				&cam_sensor_csi_mux_sel_suspend>;
		gpios = <&tlmm 28 0>,
			<&tlmm 65 0>,
			<&tlmm 59 0>;
		gpio-reset = <1>;
		gpio-custom1 = <2>;
		gpio-req-tbl-num = <0 1 2>;
		gpio-req-tbl-flags = <1 0 0>;
		gpio-req-tbl-label = "CAMIF_MCLK3",
					"CAM_RESET3",
					"CAM_CSIMUX_SEL1";
		sensor-mode = <0>;
		cci-master = <1>;
		status = "ok";
		clocks = <&gcc GCC_CAMSS_MCLK3_CLK>;
		clock-names = "cam_clk";
		clock-cntl-level = "turbo";
		clock-rates = <24000000>;
	};

    /*Aux Macro*/
	qcom,cam-sensor4 {
		cell-index = <4>;
		compatible = "qcom,cam-sensor";
		csiphy-sd-index = <1>;
		sensor-position-roll = <270>;
		sensor-position-pitch = <0>;
		sensor-position-yaw = <180>;
		//actuator-src = <&actuator_rear>;
		led-flash-src = <&led_flash_rear>;
		eeprom-src = <&eeprom_aux_macro>;
		cam_vio-supply = <&L6P>;
		cam_vana-supply = <&L4P>;
		//cam_vdig-supply = <&L2P>;
		cam_clk-supply = <&gcc_camss_top_gdsc>;
		regulator-names = "cam_vio", "cam_vana", "cam_clk";
		rgltr-cntrl-support;
		pwm-switch;
		rgltr-min-voltage = <1800000 2800000 0>;
		rgltr-max-voltage = <1800000 2800000 0>;
		rgltr-load-current = <120000 80000 0>;
		gpio-no-mux = <0>;
		pinctrl-names = "cam_default", "cam_suspend";
		pinctrl-0 = <&cam_sensor_mclk4_active
				&cam_sensor_rear3_reset_active
				&cam_sensor_csi_mux_sel_active>;
		pinctrl-1 = <&cam_sensor_mclk4_suspend
				&cam_sensor_rear3_reset_suspend
				&cam_sensor_csi_mux_sel_suspend>;
		gpios = <&tlmm 28 0>,
			<&tlmm 32 0>,
			<&tlmm 59 0>;
		gpio-reset = <1>;
		gpio-custom1 = <2>;
		gpio-req-tbl-num = <0 1 2>;
		gpio-req-tbl-flags = <1 0 0>;
		gpio-req-tbl-label = "CAMIF_MCLK4",
					"CAM_RESET4",
					"CAM_CSIMUX_SEL1";
		sensor-mode = <0>;
		cci-master = <0>;
		status = "ok";
		clocks = <&gcc GCC_CAMSS_MCLK3_CLK>;
		clock-names = "cam_clk";
		clock-cntl-level = "turbo";
		clock-rates = <24000000>;
	};
};

//#ifdef OPLUS_BUG_STABILITY
&dsi_ili9881h_boe_video {
	qcom,mdss-dsi-t-clk-post = <0x0C>;
	qcom,mdss-dsi-t-clk-pre = <0x28>;
	qcom,esd-check-enabled;
	qcom,mdss-dsi-panel-status-check-mode = "reg_read";
	qcom,mdss-dsi-panel-status-command = [06 01 00 01 00 00 01 0a];
	qcom,mdss-dsi-panel-status-command-state = "dsi_lp_mode";
	qcom,mdss-dsi-panel-status-value = <0x9c>;
	qcom,mdss-dsi-panel-on-check-value = <0x9c>;
	qcom,mdss-dsi-panel-status-read-length = <1>;
//	qcom,dsi-supported-dfps-list = <60 55 48>;
//	qcom,mdss-dsi-pan-enable-dynamic-fps;
//	qcom,mdss-dsi-pan-fps-update =
//		"dfps_immediate_porch_mode_vfp";
	qcom,dsi-select-clocks = "mux_byte_clk0", "mux_pixel_clk0",
				"src_byte_clk0", "src_pixel_clk0",
				"shadow_byte_clk0", "shadow_pixel_clk0";
//	qcom,dsi-dyn-clk-enable;
//	qcom,dsi-dyn-clk-list =
//		<976190400 988392784 984325320 980257864>;
//	qcom,dsi-dyn-clk-type = "constant-fps-adjust-vfp";
	qcom,mdss-dsi-display-timings {
		timing@0{
			qcom,mdss-dsi-panel-phy-timings =
				[21 1E 06 08 04 02 04 a0
				21 1E 06 08 04 02 04 a0
				21 1E 06 08 04 02 04 a0
				21 1E 06 08 04 02 04 a0
				21 15 06 07 04 02 04 a0];
			qcom,display-topology = <1 0 1>;
			qcom,default-topology-index = <0>;
		};
	};
};

&dsi_ili9881h_boe_90hz_video {
	qcom,mdss-dsi-t-clk-post = <0x0D>;
	qcom,mdss-dsi-t-clk-pre = <0x2E>;
	qcom,esd-check-enabled;
	qcom,mdss-dsi-panel-status-check-mode = "reg_read";
	qcom,mdss-dsi-panel-status-command = [06 01 00 01 00 00 01 0a];
	qcom,mdss-dsi-panel-status-command-state = "dsi_lp_mode";
	qcom,mdss-dsi-panel-status-value = <0x9c>;
	qcom,mdss-dsi-panel-on-check-value = <0x9c>;
	qcom,mdss-dsi-panel-status-read-length = <1>;
	qcom,dsi-supported-dfps-list = <60 90>;
	qcom,mdss-dsi-pan-enable-dynamic-fps;
	qcom,mdss-dsi-pan-fps-update =
		"dfps_immediate_porch_mode_vfp";
	qcom,mdss-dsi-min-refresh-rate = <60>;
	qcom,mdss-dsi-max-refresh-rate = <90>;
	qcom,dsi-select-clocks = "mux_byte_clk0", "mux_pixel_clk0",
				"src_byte_clk0", "src_pixel_clk0",
				"shadow_byte_clk0", "shadow_pixel_clk0";
	qcom,dsi-dyn-clk-enable;
	qcom,dsi-dyn-clk-list =
		<837423360 828118656>;
	qcom,dsi-dyn-clk-type = "constant-fps-adjust-hfp";
	qcom,mdss-dsi-display-timings {
		timing@0{
			qcom,mdss-dsi-panel-phy-timings =
				[23 1F 07 09 05 02 04 a0
				23 1F 07 09 05 02 04 a0
				23 1F 07 09 05 02 04 a0
				23 1F 07 09 05 02 04 a0
				23 1A 07 08 05 02 04 a0];
			qcom,display-topology = <1 0 1>;
			qcom,default-topology-index = <0>;
		};
	};
};

&dsi_ili9881h_hlt_90hz_video {
	qcom,mdss-dsi-t-clk-post = <0x0D>;
	qcom,mdss-dsi-t-clk-pre = <0x2E>;
	qcom,esd-check-enabled;
	qcom,mdss-dsi-panel-status-check-mode = "reg_read";
	qcom,mdss-dsi-panel-status-command = [06 01 00 01 00 00 01 0a];
	qcom,mdss-dsi-panel-status-command-state = "dsi_lp_mode";
	qcom,mdss-dsi-panel-status-value = <0x9c>;
	qcom,mdss-dsi-panel-on-check-value = <0x9c>;
	qcom,mdss-dsi-panel-status-read-length = <1>;
	qcom,dsi-supported-dfps-list = <60 90>;
	qcom,mdss-dsi-pan-enable-dynamic-fps;
	qcom,mdss-dsi-pan-fps-update =
		"dfps_immediate_porch_mode_vfp";
	qcom,mdss-dsi-min-refresh-rate = <60>;
	qcom,mdss-dsi-max-refresh-rate = <90>;
	qcom,dsi-select-clocks = "mux_byte_clk0", "mux_pixel_clk0",
				"src_byte_clk0", "src_pixel_clk0",
				"shadow_byte_clk0", "shadow_pixel_clk0";
	qcom,dsi-dyn-clk-enable;
	qcom,dsi-dyn-clk-list =
		<837423360 828118656>;
	qcom,dsi-dyn-clk-type = "constant-fps-adjust-hfp";
	qcom,mdss-dsi-display-timings {
		timing@0{
			qcom,mdss-dsi-panel-phy-timings =
				[23 1F 07 09 05 02 04 a0
				23 1F 07 09 05 02 04 a0
				23 1F 07 09 05 02 04 a0
				23 1F 07 09 05 02 04 a0
				23 1A 07 08 05 02 04 a0];
			qcom,display-topology = <1 0 1>;
			qcom,default-topology-index = <0>;
		};
	};
};

&dsi_hx83112a_tm_90hz_video {
	qcom,mdss-dsi-t-clk-post = <0x0D>;
	qcom,mdss-dsi-t-clk-pre = <0x2E>;
	qcom,esd-check-enabled;
	qcom,mdss-dsi-panel-status-check-mode = "reg_read";
	qcom,mdss-dsi-panel-status-command = [06 01 00 01 00 00 01 09];
	qcom,mdss-dsi-panel-status-command-state = "dsi_lp_mode";
	qcom,mdss-dsi-panel-status-value = <0x80 0x73 0x06>;
	qcom,mdss-dsi-panel-on-check-value = <0x80 0x73 0x06>;
	qcom,mdss-dsi-panel-status-read-length = <3>;
	qcom,dsi-supported-dfps-list = <60 90 45>;
	qcom,mdss-dsi-pan-enable-dynamic-fps;
	qcom,mdss-dsi-pan-fps-update =
		"dfps_immediate_porch_mode_vfp";
	qcom,mdss-dsi-min-refresh-rate = <45>;
	qcom,mdss-dsi-max-refresh-rate = <90>;
	qcom,dsi-select-clocks = "mux_byte_clk0", "mux_pixel_clk0",
				"src_byte_clk0", "src_pixel_clk0",
				"shadow_byte_clk0", "shadow_pixel_clk0";
	qcom,dsi-dyn-clk-enable;
	qcom,dsi-dyn-clk-list =
		<837721440 828413424>;
	qcom,dsi-dyn-clk-type = "constant-fps-adjust-hfp";
	qcom,mdss-dsi-display-timings {
		timing@0{
			qcom,mdss-dsi-panel-phy-timings =
				[23 1F 07 09 05 02 04 a0
				23 1F 07 09 05 02 04 a0
				23 1F 07 09 05 02 04 a0
				23 1F 07 09 05 02 04 a0
				23 1A 07 08 05 02 04 a0];
			qcom,display-topology = <1 0 1>;
			qcom,default-topology-index = <0>;
		};
	};
};
//#endif /* OPLUS_BUG_STABILITY */

&L7P {
	regulator-min-microvolt = <3300000>;
	regulator-max-microvolt = <3300000>;
	regulator-always-on;
};

//modify bark time to 20s
&wdog {
	/delete-property/ qcom,bark-time;
	qcom,bark-time = <20000>;
};
//#ifdef OPLUS_FEATURE_CHG_BASIC
// Yichun.Chen  PSW.BSP.CHG  2019-05-30  oppo charge edit dts
#include "oplus-charge.dtsi"
//endif

/* increase the trigger temp */
&skin_modem_trip0 {
	temperature = <80000>;
};

&skin_gold_trip {
	temperature = <80000>;
};

&skin_silver_trip {
	temperature = <81000>;
};

&skin_modem_trip1 {
	temperature = <82000>;
};

&skin_modem_trip2 {
	temperature = <83000>;
};

&skin_gpu_trip {
	temperature = <83000>;
};

&skin_modem_trip3 {
	temperature = <90000>;
};
//#endif /* OPLUS_FEATURE_THERMAL_HORAE */
